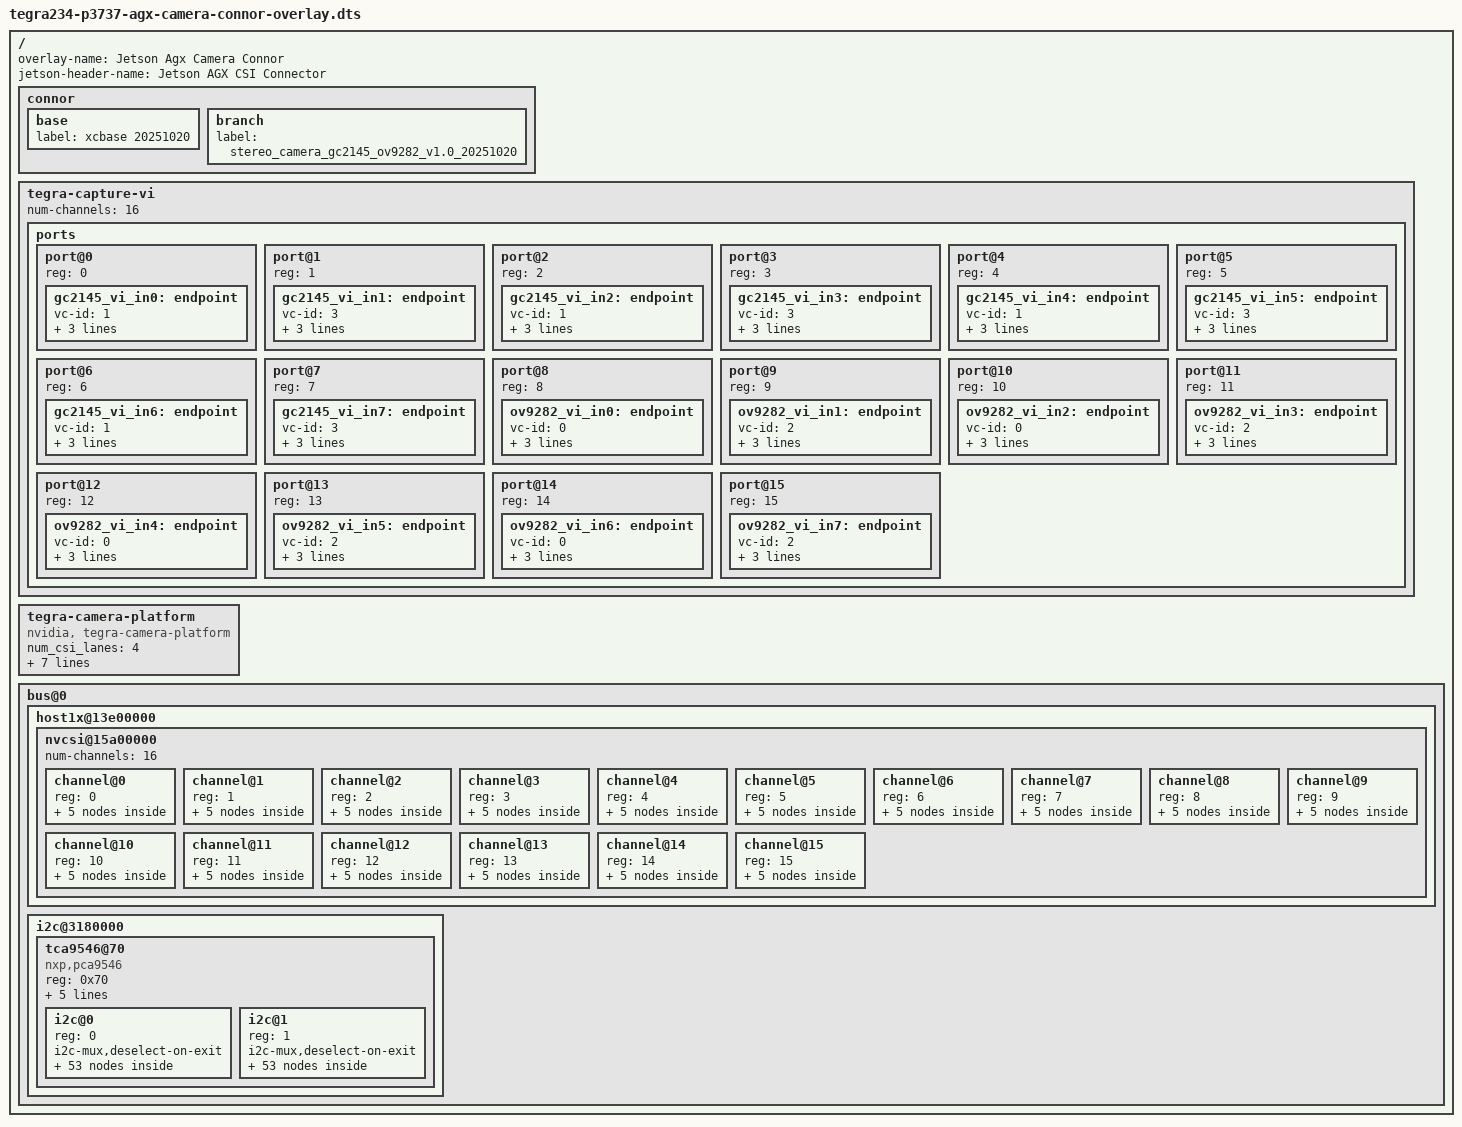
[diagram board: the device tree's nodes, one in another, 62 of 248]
// SPDX-License-Identifier: GPL-2.0-only
// SPDX-FileCopyrightText: Copyright (c) 2018-2023, NVIDIA CORPORATION & AFFILIATES. All rights reserved.

/dts-v1/;
/plugin/;

#include <dt-bindings/clock/tegra234-clock.h>
#include <dt-bindings/gpio/tegra234-gpio.h>
#include <dt-bindings/tegra234-p3737-0000+p3701-0000.h>

#define CAM0_RST_L	TEGRA234_MAIN_GPIO(H, 3)
#define CAM0_PWDN	TEGRA234_MAIN_GPIO(H, 6)
#define CAM1_RST_L	TEGRA234_MAIN_GPIO(AC, 1)
#define CAM1_PWDN	TEGRA234_MAIN_GPIO(AC, 0)
#define CAMERA_I2C_MUX_BUS(x) (0x1E + x)
#define XCFSYNC     TEGRA234_MAIN_GPIO(AC, 7)

/* camera control gpio definitions */
/ {
	overlay-name = "Jetson Agx Camera Connor";
	jetson-header-name = "Jetson AGX CSI Connector";
    compatible = JETSON_COMPATIBLE;

	fragment@0 {
		target-path = "/";

		__overlay__ {
			connor {
				base {
					label = "xcbase 20251020";
				};
				branch {
					label = "stereo_camera_gc2145_ov9282_v1.0_20251020";
				};
			};
			tegra-capture-vi {
				num-channels = <16>;
				ports {
					#address-cells = <1>;
					#size-cells = <0>;
					status = "okay";
					port@0 {
						status = "okay";
						reg = <0>;
						gc2145_vi_in0: endpoint {
							status = "okay";
							vc-id = <1>;
							port-index = <0>;
							bus-width = <4>;
							remote-endpoint = <&gc2145_csi_out0>;
						};
					};
					port@1 {
						status = "okay";
						reg = <1>;
						gc2145_vi_in1: endpoint {
							status = "okay";
							vc-id = <3>;
							port-index = <0>;
							bus-width = <4>;
							remote-endpoint = <&gc2145_csi_out1>;
						};
					};
					port@2 {
						status = "okay";
						reg = <2>;
						gc2145_vi_in2: endpoint {
							status = "okay";
							vc-id = <1>;
							port-index = <4>;
							bus-width = <4>;
							remote-endpoint = <&gc2145_csi_out2>;
						};
					};
					port@3 {
						status = "okay";
						reg = <3>;
						gc2145_vi_in3: endpoint {
							status = "okay";
							vc-id = <3>;
							port-index = <4>;
							bus-width = <4>;
							remote-endpoint = <&gc2145_csi_out3>;
						};
					};
					port@4 {
						status = "okay";
						reg = <4>;
						gc2145_vi_in4: endpoint {
							status = "okay";
							vc-id = <1>;
							port-index = <2>;
							bus-width = <4>;
							remote-endpoint = <&gc2145_csi_out4>;
						};
					};
					port@5 {
						status = "okay";
						reg = <5>;
						gc2145_vi_in5: endpoint {
							status = "okay";
							vc-id = <3>;
							port-index = <2>;
							bus-width = <4>;
							remote-endpoint = <&gc2145_csi_out5>;
						};
					};
					port@6 {
						status = "okay";
						reg = <6>;
						gc2145_vi_in6: endpoint {
							status = "okay";
							vc-id = <1>;
							port-index = <5>;
							bus-width = <4>;
							remote-endpoint = <&gc2145_csi_out6>;
						};
					};
					port@7 {
						status = "okay";
						reg = <7>;
						gc2145_vi_in7: endpoint {
							status = "okay";
							vc-id = <3>;
							port-index = <5>;
							bus-width = <4>;
							remote-endpoint = <&gc2145_csi_out7>;
						};
					};
					port@8 {
						status = "okay";
						reg = <8>;
						ov9282_vi_in0: endpoint {
							status = "okay";
							vc-id = <0>;
							port-index = <0>;
							bus-width = <4>;
							remote-endpoint = <&ov9282_csi_out0>;
						};
					};
					port@9 {
						status = "okay";
						reg = <9>;
						ov9282_vi_in1: endpoint {
							status = "okay";
							vc-id = <2>;
							port-index = <0>;
							bus-width = <4>;
							remote-endpoint = <&ov9282_csi_out1>;
						};
					};
					port@10 {
						status = "okay";
						reg = <10>;
						ov9282_vi_in2: endpoint {
							status = "okay";
							vc-id = <0>;
							port-index = <4>;
							bus-width = <4>;
							remote-endpoint = <&ov9282_csi_out2>;
						};
					};
					port@11 {
						status = "okay";
						reg = <11>;
						ov9282_vi_in3: endpoint {
							status = "okay";
							vc-id = <2>;
							port-index = <4>;
							bus-width = <4>;
							remote-endpoint = <&ov9282_csi_out3>;
						};
					};
					port@12 {
						status = "okay";
						reg = <12>;
						ov9282_vi_in4: endpoint {
							status = "okay";
							vc-id = <0>;
							port-index = <2>;
							bus-width = <4>;
							remote-endpoint = <&ov9282_csi_out4>;
						};
					};
					port@13 {
						status = "okay";
						reg = <13>;
						ov9282_vi_in5: endpoint {
							status = "okay";
							vc-id = <2>;
							port-index = <2>;
							bus-width = <4>;
							remote-endpoint = <&ov9282_csi_out5>;
						};
					};
					port@14 {
						status = "okay";
						reg = <14>;
						ov9282_vi_in6: endpoint {
							status = "okay";
							vc-id = <0>;
							port-index = <5>;
							bus-width = <4>;
							remote-endpoint = <&ov9282_csi_out6>;
						};
					};
					port@15 {
						status = "okay";
						reg = <15>;
						ov9282_vi_in7: endpoint {
							status = "okay";
							vc-id = <2>;
							port-index = <5>;
							bus-width = <4>;
							remote-endpoint = <&ov9282_csi_out7>;
						};						
					};
				};
			};
            
			tegra-camera-platform {
				compatible = "nvidia, tegra-camera-platform";
				num_csi_lanes = <4>;
				max_lane_speed = <2500000000>;
				min_bits_per_pixel = <10>;
				vi_peak_byte_per_pixel = <2>;
				vi_bw_margin_pct = <25>;
				max_pixel_rate = <165000000>;
				isp_peak_byte_per_pixel = <5>;
				isp_bw_margin_pct = <25>;
			};

			bus@0{
				host1x@13e00000 {
					nvcsi@15a00000 {
						num-channels = <16>;
						channel@0 {
							status = "okay";
							reg = <0>;
							ports {
								status = "okay";
								#address-cells = <1>;
								#size-cells = <0>;
								port@0 {
									status = "okay";
									reg = <0>;
									gc2145_csi_in0: endpoint {
										status = "okay";
										port-index = <0>;
										bus-width = <4>;
										remote-endpoint = <&gc2145_cam_out0>;
									};
								};
								port@1 {
									status = "okay";
									reg = <1>;
									gc2145_csi_out0: endpoint {
										status = "okay";
										remote-endpoint = <&gc2145_vi_in0>;
									};
								};
							};
						};
						channel@1 {
							status = "okay";
							reg = <1>;
							ports {
								status = "okay";
								#address-cells = <1>;
								#size-cells = <0>;
								port@0 {
									status = "okay";
									reg = <0>;
									gc2145_csi_in1: endpoint {
										status = "okay";
										port-index = <0>;
										bus-width = <4>;
										remote-endpoint = <&gc2145_cam_out1>;
									};
								};
								port@1 {
									status = "okay";
									reg = <1>;
									gc2145_csi_out1: endpoint {
										status = "okay";
										remote-endpoint = <&gc2145_vi_in1>;
									};
								};
							};
						};
						channel@2 {
							status = "okay";
							reg = <2>;
							ports {
								status = "okay";
								#address-cells = <1>;
								#size-cells = <0>;
								port@0 {
									status = "okay";
									reg = <0>;
									gc2145_csi_in2: endpoint {
										status = "okay";
										port-index = <4>;
										bus-width = <4>;
										remote-endpoint = <&gc2145_cam_out2>;
									};
								};
								port@1 {
									status = "okay";
									reg = <1>;
									gc2145_csi_out2: endpoint {
										status = "okay";
										remote-endpoint = <&gc2145_vi_in2>;
									};
								};
							};
						};
						channel@3 {
							status = "okay";
							reg = <3>;
							ports {
								status = "okay";
								#address-cells = <1>;
								#size-cells = <0>;
								port@0 {
									status = "okay";
									reg = <0>;
									gc2145_csi_in3: endpoint {
										status = "okay";
										port-index = <4>;
										bus-width = <4>;
										remote-endpoint = <&gc2145_cam_out3>;
									};
								};
								port@1 {
									status = "okay";
									reg = <1>;
									gc2145_csi_out3: endpoint {
										status = "okay";
										remote-endpoint = <&gc2145_vi_in3>;
									};
								};
							};
						};
						channel@4 {
							status = "okay";
							reg = <4>;
							ports {
								status = "okay";
								#address-cells = <1>;
								#size-cells = <0>;
								port@0 {
									status = "okay";
									reg = <0>;
									gc2145_csi_in4: endpoint {
										status = "okay";
										port-index = <2>;
										bus-width = <4>;
										remote-endpoint = <&gc2145_cam_out4>;
									};
								};
								port@1 {
									status = "okay";
									reg = <1>;
									gc2145_csi_out4: endpoint {
										status = "okay";
										remote-endpoint = <&gc2145_vi_in4>;
									};
								};
							};
						};
						channel@5 {
							status = "okay";
							reg = <5>;
							ports {
								status = "okay";
								#address-cells = <1>;
								#size-cells = <0>;
								port@0 {
									status = "okay";
									reg = <0>;
									gc2145_csi_in5: endpoint {
										status = "okay";
										port-index = <2>;
										bus-width = <4>;
										remote-endpoint = <&gc2145_cam_out5>;
									};
								};
								port@1 {
									status = "okay";
									reg = <1>;
									gc2145_csi_out5: endpoint {
										status = "okay";
										remote-endpoint = <&gc2145_vi_in5>;
									};
								};
							};
						};
						channel@6 {
							status = "okay";
							reg = <6>;
							ports {
								status = "okay";
								#address-cells = <1>;
								#size-cells = <0>;
								port@0 {
									status = "okay";
									reg = <0>;
									gc2145_csi_in6: endpoint {
										status = "okay";
										port-index = <6>;
										bus-width = <4>;
										remote-endpoint = <&gc2145_cam_out6>;
									};
								};
								port@1 {
									status = "okay";
									reg = <1>;
									gc2145_csi_out6: endpoint {
										status = "okay";
										remote-endpoint = <&gc2145_vi_in6>;
									};
								};
							};
						};
						channel@7 {
							status = "okay";
							reg = <7>;
							ports {
								status = "okay";
								#address-cells = <1>;
								#size-cells = <0>;
								port@0 {
									status = "okay";
									reg = <0>;
									gc2145_csi_in7: endpoint {
										status = "okay";
										port-index = <6>;
										bus-width = <4>;
										remote-endpoint = <&gc2145_cam_out7>;
									};
								};
								port@1 {
									status = "okay";
									reg = <1>;
									gc2145_csi_out7: endpoint {
										status = "okay";
										remote-endpoint = <&gc2145_vi_in7>;
									};
								};
							};
						};
						channel@8 {
							status = "okay";
							reg = <8>;
							ports {
								status = "okay";
								#address-cells = <1>;
								#size-cells = <0>;
								port@0 {
									status = "okay";
									reg = <0>;
									ov9282_csi_in0: endpoint {
										status = "okay";
										port-index = <0>;
										bus-width = <4>;
										remote-endpoint = <&ov9282_cam_out0>;
									};
								};
								port@1 {
									status = "okay";
									reg = <1>;
									ov9282_csi_out0: endpoint {
										status = "okay";
										remote-endpoint = <&ov9282_vi_in0>;
									};
								};
							};
						};
						channel@9 {
							status = "okay";
							reg = <9>;
							ports {
								status = "okay";
								#address-cells = <1>;
								#size-cells = <0>;
								port@0 {
									status = "okay";
									reg = <0>;
									ov9282_csi_in1: endpoint {
										status = "okay";
										port-index = <0>;
										bus-width = <4>;
										remote-endpoint = <&ov9282_cam_out1>;
									};
								};
								port@1 {
									status = "okay";
									reg = <1>;
									ov9282_csi_out1: endpoint {
										status = "okay";
										remote-endpoint = <&ov9282_vi_in1>;
									};
								};
							};
						};
						channel@10 {
							status = "okay";
							reg = <10>;
							ports {
								status = "okay";
								#address-cells = <1>;
								#size-cells = <0>;
								port@0 {
									status = "okay";
									reg = <0>;
									ov9282_csi_in2: endpoint {
										status = "okay";
										port-index = <4>;
										bus-width = <4>;
										remote-endpoint = <&ov9282_cam_out2>;
									};
								};
								port@1 {
									status = "okay";
									reg = <1>;
									ov9282_csi_out2: endpoint {
										status = "okay";
										remote-endpoint = <&ov9282_vi_in2>;
									};
								};
							};
						};
						channel@11 {
							status = "okay";
							reg = <11>;
							ports {
								status = "okay";
								#address-cells = <1>;
								#size-cells = <0>;
								port@0 {
									status = "okay";
									reg = <0>;
									ov9282_csi_in3: endpoint {
										status = "okay";
										port-index = <4>;
										bus-width = <4>;
										remote-endpoint = <&ov9282_cam_out3>;
									};
								};
								port@1 {
									status = "okay";
									reg = <1>;
									ov9282_csi_out3: endpoint {
										status = "okay";
										remote-endpoint = <&ov9282_vi_in3>;
									};
								};
							};
						};
						channel@12 {
							status = "okay";
							reg = <12>;
							ports {
								status = "okay";
								#address-cells = <1>;
								#size-cells = <0>;
								port@0 {
									status = "okay";
									reg = <0>;
									ov9282_csi_in4: endpoint {
										status = "okay";
										port-index = <2>;
										bus-width = <4>;
										remote-endpoint = <&ov9282_cam_out4>;
									};
								};
								port@1 {
									status = "okay";
									reg = <1>;
									ov9282_csi_out4: endpoint {
										status = "okay";
										remote-endpoint = <&ov9282_vi_in4>;
									};
								};
							};
						};
						channel@13 {
							status = "okay";
							reg = <13>;
							ports {
								status = "okay";
								#address-cells = <1>;
								#size-cells = <0>;
								port@0 {
									status = "okay";
									reg = <0>;
									ov9282_csi_in5: endpoint {
										status = "okay";
										port-index = <2>;
										bus-width = <4>;
										remote-endpoint = <&ov9282_cam_out5>;
									};
								};
								port@1 {
									status = "okay";
									reg = <1>;
									ov9282_csi_out5: endpoint {
										status = "okay";
										remote-endpoint = <&ov9282_vi_in5>;
									};
								};
							};
						};
						channel@14 {
							status = "okay";
							reg = <14>;
							ports {
								status = "okay";
								#address-cells = <1>;
								#size-cells = <0>;
								port@0 {
									status = "okay";
									reg = <0>;
									ov9282_csi_in6: endpoint {
										status = "okay";
										port-index = <6>;
										bus-width = <4>;
										remote-endpoint = <&ov9282_cam_out6>;
									};
								};
								port@1 {
									status = "okay";
									reg = <1>;
									ov9282_csi_out6: endpoint {
										status = "okay";
										remote-endpoint = <&ov9282_vi_in6>;
									};
								};
							};
						};
						channel@15 {
							status = "okay";
							reg = <15>;
							ports {
								status = "okay";
								#address-cells = <1>;
								#size-cells = <0>;
								port@0 {
									status = "okay";
									reg = <0>;
									ov9282_csi_in7: endpoint {
										status = "okay";
										port-index = <6>;
										bus-width = <4>;
										remote-endpoint = <&ov9282_cam_out7>;
									};
								};
								port@1 {
									status = "okay";
									reg = <1>;
									ov9282_csi_out7: endpoint {
										status = "okay";
										remote-endpoint = <&ov9282_vi_in7>;
									};
								};
							};
						};
					};
				};

                i2c@3180000 {
					tca9546@70 {
						status = "okay";
						compatible = "nxp,pca9546";
						reg = <0x70>;
						#address-cells = <1>;
						#size-cells = <0>;
						skip_mux_detect = "yes";
						force_bus_start = <CAMERA_I2C_MUX_BUS(0)>;
						vif-supply = <&vdd_1v8_sys>;
						vcc-supply = <&vdd_1v8_sys>;
						vcc_lp = "vcc";
						i2c@0 {
							reg = <0>;
							i2c-mux,deselect-on-exit;
							#address-cells = <1>;
							#size-cells = <0>;
							status = "okay";
							dser_0: max96712 {
								status = "okay";
								compatible = "Connor,abh_max96712";
                    			reg = <0x29>;
								is-master;
                			};
							gc2145_a {
								status = "okay";
								def-addr = <0x3c>; /* actual i2c address of sensor */
								nvidia,gmsl-dser-device = <&dser_0>;
								des-link = "A";

								compatible = "Connor,abh_max9295d";

								reg = <0x10>; /* 9295 will translate to this i2c address */

								physical_w = "15.0";
								physical_h = "12.5";
								sensor_model ="gc2145";
								post_crop_frame_drop = "0";
								use_decibel_gain = "true";

								/* enable CID_SENSOR_MODE_ID for sensor modes selection */
								use_sensor_mode_id = "true";

								mode0 {
									mclk_khz = "24000";
									num_lanes = "2";
									tegra_sinterface = "serial_a";
									vc_id = "0";
									discontinuous_clk = "yes";
									dpcm_enable = "false";
									cil_settletime = "0";
									dynamic_pixel_bit_depth = "16";
									csi_pixel_bit_depth = "16"; 
									mode_type = "yuv";
									pixel_phase = "uyvy";

									active_w = "1600";
									active_h = "1200";
									readout_orientation = "0";
									line_length = "2800";
									inherent_gain = "1";
									pix_clk_hz = "165000000";
									serdes_pix_clk_hz = "2400000000";

									gain_factor = "10";
									min_gain_val = "0"; /* dB */
									max_gain_val = "420"; /* dB */
									step_gain_val = "3"; /* 0.3 */
									default_gain = "150";
									min_hdr_ratio = "1";
									max_hdr_ratio = "1";
									framerate_factor = "1000000";
									min_framerate = "30000000";
									max_framerate = "30000000";
									step_framerate = "1";
									default_framerate = "30000000";
									exposure_factor = "1000000";
									min_exp_time = "59"; /*us, 2 lines*/
									max_exp_time = "33333";
									step_exp_time = "1";
									default_exp_time = "33333";/* us */
									embedded_metadata_height = "0";
								};

								mode1 {
									mclk_khz = "24000";
									num_lanes = "2";
									tegra_sinterface = "serial_a";
									vc_id = "0";
									discontinuous_clk = "yes";
									dpcm_enable = "false";
									cil_settletime = "0";
									dynamic_pixel_bit_depth = "16";
									csi_pixel_bit_depth = "16"; 
									mode_type = "yuv";
									pixel_phase = "uyvy";

									active_w = "1280";
									active_h = "720";
									readout_orientation = "0";
									line_length = "2800";
									inherent_gain = "1";
									pix_clk_hz = "165000000";
									serdes_pix_clk_hz = "2400000000";

									gain_factor = "10";
									min_gain_val = "0"; /* dB */
									max_gain_val = "420"; /* dB */
									step_gain_val = "3"; /* 0.3 */
									default_gain = "150";
									min_hdr_ratio = "1";
									max_hdr_ratio = "1";
									framerate_factor = "1000000";
									min_framerate = "30000000";
									max_framerate = "30000000";
									step_framerate = "1";
									default_framerate = "30000000";
									exposure_factor = "1000000";
									min_exp_time = "59"; /*us, 2 lines*/
									max_exp_time = "33333";
									step_exp_time = "1";
									default_exp_time = "33333";/* us */
									embedded_metadata_height = "0";
								};

								ports {
									#address-cells = <1>;
									#size-cells = <0>;
									port@0 {
										reg = <0>;
										gc2145_cam_out0: endpoint {
											vc-id = <1>;
											port-index = <0>;
											bus-width = <4>;
											remote-endpoint = <&gc2145_csi_in0>;
										};
									};
								};
								gmsl-link {
									num-ser-lanes = <2>;
									streams = "yuv16";
								};
							};
							gc2145_b {
								status = "okay";
								def-addr = <0x3c>; /* actual i2c address of sensor */
								nvidia,gmsl-dser-device = <&dser_0>;
								des-link = "B";

								compatible = "Connor,abh_max9295d";

								reg = <0x11>; /* 9295 will translate to this i2c address */

								physical_w = "15.0";
								physical_h = "12.5";
								sensor_model ="gc2145";
								post_crop_frame_drop = "0";
								use_decibel_gain = "true";

								/* enable CID_SENSOR_MODE_ID for sensor modes selection */
								use_sensor_mode_id = "true";
								
								mode0 {
									mclk_khz = "24000";
									num_lanes = "2";
									tegra_sinterface = "serial_a";
									vc_id = "2";
									discontinuous_clk = "no";
									dpcm_enable = "false";
									cil_settletime = "0";
									dynamic_pixel_bit_depth = "16";
									csi_pixel_bit_depth = "16"; 
									mode_type = "yuv";
									pixel_phase = "uyvy";

									active_w = "1600";
									active_h = "1200";
									readout_orientation = "0";
									line_length = "2800";
									inherent_gain = "1";
									pix_clk_hz = "165000000";
									serdes_pix_clk_hz = "2400000000";

									gain_factor = "10";
									min_gain_val = "0"; /* dB */
									max_gain_val = "420"; /* dB */
									step_gain_val = "3"; /* 0.3 */
									default_gain = "150";
									min_hdr_ratio = "1";
									max_hdr_ratio = "1";
									framerate_factor = "1000000";
									min_framerate = "30000000";
									max_framerate = "30000000";
									step_framerate = "1";
									default_framerate = "30000000";
									exposure_factor = "1000000";
									min_exp_time = "59"; /*us, 2 lines*/
									max_exp_time = "33333";
									step_exp_time = "1";
									default_exp_time = "33333";/* us */
									embedded_metadata_height = "0";
								};
								mode1 {
									mclk_khz = "24000";
									num_lanes = "2";
									tegra_sinterface = "serial_a";
									vc_id = "2";
									discontinuous_clk = "yes";
									dpcm_enable = "false";
									cil_settletime = "0";
									dynamic_pixel_bit_depth = "16";
									csi_pixel_bit_depth = "16"; 
									mode_type = "yuv";
									pixel_phase = "uyvy";

									active_w = "1280";
									active_h = "720";
									readout_orientation = "0";
									line_length = "2800";
									inherent_gain = "1";
									pix_clk_hz = "165000000";
									serdes_pix_clk_hz = "2400000000";

									gain_factor = "10";
									min_gain_val = "0"; /* dB */
									max_gain_val = "420"; /* dB */
									step_gain_val = "3"; /* 0.3 */
									default_gain = "150";
									min_hdr_ratio = "1";
									max_hdr_ratio = "1";
									framerate_factor = "1000000";
									min_framerate = "30000000";
									max_framerate = "30000000";
									step_framerate = "1";
									default_framerate = "30000000";
									exposure_factor = "1000000";
									min_exp_time = "59"; /*us, 2 lines*/
									max_exp_time = "33333";
									step_exp_time = "1";
									default_exp_time = "33333";/* us */
									embedded_metadata_height = "0";
								};

								ports {
									#address-cells = <1>;
									#size-cells = <0>;
									port@0 {
										reg = <0>;
										gc2145_cam_out1: endpoint {
											vc-id = <3>;
											port-index = <0>;
											bus-width = <4>;
											remote-endpoint = <&gc2145_csi_in1>;
										};
									};
								};
								gmsl-link {
									num-ser-lanes = <2>;
									streams = "yuv16";
								};
							};
							gc2145_c {
								status = "okay";
								def-addr = <0x3c>; /* actual i2c address of sensor */
								nvidia,gmsl-dser-device = <&dser_0>;
								des-link = "C";

								compatible = "Connor,abh_max9295d";

								reg = <0x12>; /* 9295 will translate to this i2c address */

								physical_w = "15.0";
								physical_h = "12.5";
								sensor_model ="gc2145";
								post_crop_frame_drop = "0";
								use_decibel_gain = "true";

								/* enable CID_SENSOR_MODE_ID for sensor modes selection */
								use_sensor_mode_id = "true";

								mode0 {
									
									mclk_khz = "24000";
									num_lanes = "2";
									tegra_sinterface = "serial_a";
									vc_id = "2";
									discontinuous_clk = "yes";
									dpcm_enable = "false";
									cil_settletime = "0";
									dynamic_pixel_bit_depth = "16";
									csi_pixel_bit_depth = "16"; 
									mode_type = "yuv";
									pixel_phase = "uyvy";

									active_w = "1600";
									active_h = "1200";
									readout_orientation = "0";
									line_length = "2800";
									inherent_gain = "1";
									pix_clk_hz = "165000000";
									serdes_pix_clk_hz = "2400000000";

									gain_factor = "10";
									min_gain_val = "0"; /* dB */
									max_gain_val = "420"; /* dB */
									step_gain_val = "3"; /* 0.3 */
									default_gain = "150";
									min_hdr_ratio = "1";
									max_hdr_ratio = "1";
									framerate_factor = "1000000";
									min_framerate = "30000000";
									max_framerate = "30000000";
									step_framerate = "1";
									default_framerate = "30000000";
									exposure_factor = "1000000";
									min_exp_time = "59"; /*us, 2 lines*/
									max_exp_time = "33333";
									step_exp_time = "1";
									default_exp_time = "33333";/* us */
									embedded_metadata_height = "0";
								};

								mode1 {
									mclk_khz = "24000";
									num_lanes = "2";
									tegra_sinterface = "serial_a";
									vc_id = "2";
									discontinuous_clk = "yes";
									dpcm_enable = "false";
									cil_settletime = "0";
									dynamic_pixel_bit_depth = "16";
									csi_pixel_bit_depth = "16"; 
									mode_type = "yuv";
									pixel_phase = "uyvy";

									active_w = "1280";
									active_h = "720";
									readout_orientation = "0";
									line_length = "2800";
									inherent_gain = "1";
									pix_clk_hz = "165000000";
									serdes_pix_clk_hz = "2400000000";

									gain_factor = "10";
									min_gain_val = "0"; /* dB */
									max_gain_val = "420"; /* dB */
									step_gain_val = "3"; /* 0.3 */
									default_gain = "150";
									min_hdr_ratio = "1";
									max_hdr_ratio = "1";
									framerate_factor = "1000000";
									min_framerate = "30000000";
									max_framerate = "30000000";
									step_framerate = "1";
									default_framerate = "30000000";
									exposure_factor = "1000000";
									min_exp_time = "59"; /*us, 2 lines*/
									max_exp_time = "33333";
									step_exp_time = "1";
									default_exp_time = "33333";/* us */
									embedded_metadata_height = "0";
								};
								ports {
									#address-cells = <1>;
									#size-cells = <0>;
									port@0 {
										reg = <0>;
										gc2145_cam_out2: endpoint {
											vc-id = <1>;
											port-index = <4>;
											bus-width = <4>;
											remote-endpoint = <&gc2145_csi_in2>;
										};
									};
								};
								gmsl-link {
									num-ser-lanes = <2>;
									streams = "yuv16";
								};
							};
							gc2145_d {
								status = "okay";
								def-addr = <0x3c>; /* actual i2c address of sensor */
								nvidia,gmsl-dser-device = <&dser_0>;
								des-link = "D";

								compatible = "Connor,abh_max9295d";

								reg = <0x13>; /* 9295 will translate to this i2c address */

								physical_w = "15.0";
								physical_h = "12.5";
								sensor_model ="gc2145";
								post_crop_frame_drop = "0";
								use_decibel_gain = "true";

								/* enable CID_SENSOR_MODE_ID for sensor modes selection */
								use_sensor_mode_id = "true";

								mode0 {
									
									mclk_khz = "24000";
									num_lanes = "2";
									tegra_sinterface = "serial_a";
									vc_id = "2";
									discontinuous_clk = "no";
									dpcm_enable = "false";
									cil_settletime = "0";
									dynamic_pixel_bit_depth = "16";
									csi_pixel_bit_depth = "16"; 
									mode_type = "yuv";
									pixel_phase = "uyvy";

									active_w = "1600";
									active_h = "1200";
									readout_orientation = "0";
									line_length = "2800";
									inherent_gain = "1";
									pix_clk_hz = "165000000";
									serdes_pix_clk_hz = "2400000000";

									gain_factor = "10";
									min_gain_val = "0"; /* dB */
									max_gain_val = "420"; /* dB */
									step_gain_val = "3"; /* 0.3 */
									default_gain = "150";
									min_hdr_ratio = "1";
									max_hdr_ratio = "1";
									framerate_factor = "1000000";
									min_framerate = "30000000";
									max_framerate = "30000000";
									step_framerate = "1";
									default_framerate = "30000000";
									exposure_factor = "1000000";
									min_exp_time = "59"; /*us, 2 lines*/
									max_exp_time = "33333";
									step_exp_time = "1";
									default_exp_time = "33333";/* us */
									embedded_metadata_height = "0";
								};
								mode1 {
									mclk_khz = "24000";
									num_lanes = "2";
									tegra_sinterface = "serial_a";
									vc_id = "2";
									discontinuous_clk = "yes";
									dpcm_enable = "false";
									cil_settletime = "0";
									dynamic_pixel_bit_depth = "16";
									csi_pixel_bit_depth = "16"; 
									mode_type = "yuv";
									pixel_phase = "uyvy";

									active_w = "1280";
									active_h = "720";
									readout_orientation = "0";
									line_length = "2800";
									inherent_gain = "1";
									pix_clk_hz = "165000000";
									serdes_pix_clk_hz = "2400000000";

									gain_factor = "10";
									min_gain_val = "0"; /* dB */
									max_gain_val = "420"; /* dB */
									step_gain_val = "3"; /* 0.3 */
									default_gain = "150";
									min_hdr_ratio = "1";
									max_hdr_ratio = "1";
									framerate_factor = "1000000";
									min_framerate = "30000000";
									max_framerate = "30000000";
									step_framerate = "1";
									default_framerate = "30000000";
									exposure_factor = "1000000";
									min_exp_time = "59"; /*us, 2 lines*/
									max_exp_time = "33333";
									step_exp_time = "1";
									default_exp_time = "33333";/* us */
									embedded_metadata_height = "0";
								};

								ports {
									#address-cells = <1>;
									#size-cells = <0>;
									port@0 {
										reg = <0>;
										gc2145_cam_out3: endpoint {
											vc-id = <3>;
											port-index = <4>;
											bus-width = <4>;
											remote-endpoint = <&gc2145_csi_in3>;
										};
									};
								};
								gmsl-link {
									num-ser-lanes = <2>;
									streams = "yuv16";
								};
							};

							ov9282_a {
								status = "okay";
								def-addr = <0x37>; /* actual i2c address of sensor */
								nvidia,gmsl-dser-device = <&dser_0>;
								des-link = "A";

								compatible = "Connor,abh_deepth_max9295d";

								reg = <0x14>; /* 9295 will translate to this i2c address */

								physical_w = "15.0";
								physical_h = "12.5";
								sensor_model ="ov9282";
								post_crop_frame_drop = "0";
								use_decibel_gain = "true";

								/* enable CID_SENSOR_MODE_ID for sensor modes selection */
								use_sensor_mode_id = "true";

								mode0 {
									mclk_khz = "24000";
									num_lanes = "2";
									tegra_sinterface = "serial_a";
									vc_id = "1";
									discontinuous_clk = "no";
									dpcm_enable = "false";
									cil_settletime = "0";
									dynamic_pixel_bit_depth = "8";
									csi_pixel_bit_depth = "8"; 
									mode_type = "bayer";
									pixel_phase = "bggr";
									pixel_t = "bayer_bggr8";

									active_w = "1280";
									active_h = "400";
									readout_orientation = "0";
									line_length = "2200";
									inherent_gain = "1";
									pix_clk_hz = "165000000";
									serdes_pix_clk_hz = "2400000000";

									gain_factor = "10";
									min_gain_val = "0"; /* dB */
									max_gain_val = "420"; /* dB */
									step_gain_val = "3"; /* 0.3 */
									default_gain = "150";
									min_hdr_ratio = "1";
									max_hdr_ratio = "1";
									framerate_factor = "1000000";
									min_framerate = "30000000";
									max_framerate = "30000000";
									step_framerate = "1";
									default_framerate = "30000000";
									exposure_factor = "1000000";
									min_exp_time = "59"; /*us, 2 lines*/
									max_exp_time = "33333";
									step_exp_time = "1";
									default_exp_time = "33333";/* us */
									embedded_metadata_height = "0";
								};
								ports {
									#address-cells = <1>;
									#size-cells = <0>;
									port@0 {
										reg = <0>;
										ov9282_cam_out0: endpoint {
											vc-id = <0>;
											port-index = <0>;
											bus-width = <4>;
											remote-endpoint = <&ov9282_csi_in0>;
										};
									};
								};
								gmsl-link {
									num-ser-lanes = <2>;
									streams = "raw8";
								};
							};
							ov9282_b {
								status = "okay";
								def-addr = <0x37>; /* actual i2c address of sensor */
								nvidia,gmsl-dser-device = <&dser_0>;
								des-link = "B";

								compatible = "Connor,abh_deepth_max9295d";

								reg = <0x15>; /* 9295 will translate to this i2c address */

								physical_w = "15.0";
								physical_h = "12.5";
								sensor_model ="ov9282";
								post_crop_frame_drop = "0";
								use_decibel_gain = "true";

								/* enable CID_SENSOR_MODE_ID for sensor modes selection */
								use_sensor_mode_id = "true";

								mode0 {
									mclk_khz = "24000";
									num_lanes = "2";
									tegra_sinterface = "serial_a";
									vc_id = "3";
									discontinuous_clk = "no";
									dpcm_enable = "false";
									cil_settletime = "0";
									dynamic_pixel_bit_depth = "8";
									csi_pixel_bit_depth = "8"; 
									mode_type = "bayer";
									pixel_phase = "bggr";
									pixel_t = "bayer_bggr8";

									active_w = "1280";
									active_h = "400";
									readout_orientation = "0";
									line_length = "2200";
									inherent_gain = "1";
									pix_clk_hz = "165000000";
									serdes_pix_clk_hz = "2400000000";

									gain_factor = "10";
									min_gain_val = "0"; /* dB */
									max_gain_val = "420"; /* dB */
									step_gain_val = "3"; /* 0.3 */
									default_gain = "150";
									min_hdr_ratio = "1";
									max_hdr_ratio = "1";
									framerate_factor = "1000000";
									min_framerate = "30000000";
									max_framerate = "30000000";
									step_framerate = "1";
									default_framerate = "30000000";
									exposure_factor = "1000000";
									min_exp_time = "59"; /*us, 2 lines*/
									max_exp_time = "33333";
									step_exp_time = "1";
									default_exp_time = "33333";/* us */
									embedded_metadata_height = "0";
								};
								ports {
									#address-cells = <1>;
									#size-cells = <0>;
									port@0 {
										reg = <0>;
										ov9282_cam_out1: endpoint {
											vc-id = <2>;
											port-index = <0>;
											bus-width = <4>;
											remote-endpoint = <&ov9282_csi_in1>;
										};
									};
								};
								gmsl-link {
									num-ser-lanes = <2>;
									streams = "raw8";
								};
							};
							ov9282_c {
								status = "okay";
								def-addr = <0x37>; /* actual i2c address of sensor */
								nvidia,gmsl-dser-device = <&dser_0>;
								des-link = "C";

								compatible = "Connor,abh_deepth_max9295d";

								reg = <0x16>; /* 9295 will translate to this i2c address */

								physical_w = "15.0";
								physical_h = "12.5";
								sensor_model ="ov9282";
								post_crop_frame_drop = "0";
								use_decibel_gain = "true";

								/* enable CID_SENSOR_MODE_ID for sensor modes selection */
								use_sensor_mode_id = "true";

								mode0 {
									
									mclk_khz = "24000";
									num_lanes = "2";
									tegra_sinterface = "serial_a";
									vc_id = "1";
									discontinuous_clk = "no";
									dpcm_enable = "false";
									cil_settletime = "0";
									dynamic_pixel_bit_depth = "8";
									csi_pixel_bit_depth = "8"; 
									mode_type = "bayer";
									pixel_phase = "bggr";
									pixel_t = "bayer_bggr8";

									active_w = "1280";
									active_h = "400";
									readout_orientation = "0";
									line_length = "2200";
									inherent_gain = "1";
									pix_clk_hz = "165000000";
									serdes_pix_clk_hz = "2400000000";

									gain_factor = "10";
									min_gain_val = "0"; /* dB */
									max_gain_val = "420"; /* dB */
									step_gain_val = "3"; /* 0.3 */
									default_gain = "150";
									min_hdr_ratio = "1";
									max_hdr_ratio = "1";
									framerate_factor = "1000000";
									min_framerate = "30000000";
									max_framerate = "30000000";
									step_framerate = "1";
									default_framerate = "30000000";
									exposure_factor = "1000000";
									min_exp_time = "59"; /*us, 2 lines*/
									max_exp_time = "33333";
									step_exp_time = "1";
									default_exp_time = "33333";/* us */
									embedded_metadata_height = "0";
								};
								ports {
									#address-cells = <1>;
									#size-cells = <0>;
									port@0 {
										reg = <0>;
										ov9282_cam_out2: endpoint {
											vc-id = <0>;
											port-index = <4>;
											bus-width = <4>;
											remote-endpoint = <&ov9282_csi_in2>;
										};
									};
								};
								gmsl-link {
									num-ser-lanes = <2>;
									streams = "raw8";
								};
							};
							ov9282_d {
								status = "okay";
								def-addr = <0x37>; /* actual i2c address of sensor */
								nvidia,gmsl-dser-device = <&dser_0>;
								des-link = "D";

								compatible = "Connor,abh_deepth_max9295d";

								reg = <0x17>; /* 9295 will translate to this i2c address */

								physical_w = "15.0";
								physical_h = "12.5";
								sensor_model ="ov9282";
								post_crop_frame_drop = "0";
								use_decibel_gain = "true";

								/* enable CID_SENSOR_MODE_ID for sensor modes selection */
								use_sensor_mode_id = "true";

								mode0 {
									
									mclk_khz = "24000";
									num_lanes = "2";
									tegra_sinterface = "serial_a";
									vc_id = "3";
									discontinuous_clk = "no";
									dpcm_enable = "false";
									cil_settletime = "0";
									dynamic_pixel_bit_depth = "8";
									csi_pixel_bit_depth = "8"; 
									mode_type = "bayer";
									pixel_t = "bayer_bggr8";
									pixel_phase = "bggr";

									active_w = "1280";
									active_h = "400";
									readout_orientation = "0";
									line_length = "2200";
									inherent_gain = "1";
									pix_clk_hz = "165000000";
									serdes_pix_clk_hz = "2400000000";

									gain_factor = "10";
									min_gain_val = "0"; /* dB */
									max_gain_val = "420"; /* dB */
									step_gain_val = "3"; /* 0.3 */
									default_gain = "150";
									min_hdr_ratio = "1";
									max_hdr_ratio = "1";
									framerate_factor = "1000000";
									min_framerate = "30000000";
									max_framerate = "30000000";
									step_framerate = "1";
									default_framerate = "30000000";
									exposure_factor = "1000000";
									min_exp_time = "59"; /*us, 2 lines*/
									max_exp_time = "33333";
									step_exp_time = "1";
									default_exp_time = "33333";/* us */
									embedded_metadata_height = "0";
								};

								ports {
									#address-cells = <1>;
									#size-cells = <0>;
									port@0 {
										reg = <0>;
										ov9282_cam_out3: endpoint {
											vc-id = <2>;
											port-index = <4>;
											bus-width = <4>;
											remote-endpoint = <&ov9282_csi_in3>;
										};
									};
								};
								gmsl-link {
									num-ser-lanes = <2>;
									streams = "raw8";
								};
							};
						};
						i2c@1 {
							reg = <1>;
							i2c-mux,deselect-on-exit;
							#address-cells = <1>;
							#size-cells = <0>;
							status = "okay";
							dser_1: max96712 {
								status = "okay";
								compatible = "Connor,abh_max96712";
                    			reg = <0x29>;
                			};
							gc2145_a {
								status = "okay";
								def-addr = <0x3c>; /* actual i2c address of sensor */
								nvidia,gmsl-dser-device = <&dser_1>;
								des-link = "A";

								compatible = "Connor,abh_max9295d";

								reg = <0x10>; /* 9295 will translate to this i2c address */

								physical_w = "15.0";
								physical_h = "12.5";
								sensor_model ="gc2145";
								post_crop_frame_drop = "0";
								use_decibel_gain = "true";

								/* enable CID_SENSOR_MODE_ID for sensor modes selection */
								use_sensor_mode_id = "true";

								mode0 {
									mclk_khz = "24000";
									num_lanes = "2";
									tegra_sinterface = "serial_a";
									vc_id = "0";
									discontinuous_clk = "yes";
									dpcm_enable = "false";
									cil_settletime = "0";
									dynamic_pixel_bit_depth = "16";
									csi_pixel_bit_depth = "16"; 
									mode_type = "yuv";
									pixel_phase = "uyvy";

									active_w = "1600";
									active_h = "1200";
									readout_orientation = "0";
									line_length = "2800";
									inherent_gain = "1";
									pix_clk_hz = "165000000";
									serdes_pix_clk_hz = "2400000000";

									gain_factor = "10";
									min_gain_val = "0"; /* dB */
									max_gain_val = "420"; /* dB */
									step_gain_val = "3"; /* 0.3 */
									default_gain = "150";
									min_hdr_ratio = "1";
									max_hdr_ratio = "1";
									framerate_factor = "1000000";
									min_framerate = "30000000";
									max_framerate = "30000000";
									step_framerate = "1";
									default_framerate = "30000000";
									exposure_factor = "1000000";
									min_exp_time = "59"; /*us, 2 lines*/
									max_exp_time = "33333";
									step_exp_time = "1";
									default_exp_time = "33333";/* us */
									embedded_metadata_height = "0";
								};

								mode1 {
									mclk_khz = "24000";
									num_lanes = "2";
									tegra_sinterface = "serial_a";
									vc_id = "0";
									discontinuous_clk = "yes";
									dpcm_enable = "false";
									cil_settletime = "0";
									dynamic_pixel_bit_depth = "16";
									csi_pixel_bit_depth = "16"; 
									mode_type = "yuv";
									pixel_phase = "uyvy";

									active_w = "1280";
									active_h = "720";
									readout_orientation = "0";
									line_length = "2800";
									inherent_gain = "1";
									pix_clk_hz = "165000000";
									serdes_pix_clk_hz = "2400000000";

									gain_factor = "10";
									min_gain_val = "0"; /* dB */
									max_gain_val = "420"; /* dB */
									step_gain_val = "3"; /* 0.3 */
									default_gain = "150";
									min_hdr_ratio = "1";
									max_hdr_ratio = "1";
									framerate_factor = "1000000";
									min_framerate = "30000000";
									max_framerate = "30000000";
									step_framerate = "1";
									default_framerate = "30000000";
									exposure_factor = "1000000";
									min_exp_time = "59"; /*us, 2 lines*/
									max_exp_time = "33333";
									step_exp_time = "1";
									default_exp_time = "33333";/* us */
									embedded_metadata_height = "0";
								};

								ports {
									#address-cells = <1>;
									#size-cells = <0>;
									port@0 {
										reg = <0>;
										gc2145_cam_out4: endpoint {
											vc-id = <1>;
											port-index = <2>;
											bus-width = <4>;
											remote-endpoint = <&gc2145_csi_in4>;
										};
									};
								};
								gmsl-link {
									num-ser-lanes = <2>;
									streams = "yuv16";
								};
							};
							gc2145_b {
								status = "okay";
								def-addr = <0x3c>; /* actual i2c address of sensor */
								nvidia,gmsl-dser-device = <&dser_1>;
								des-link = "B";

								compatible = "Connor,abh_max9295d";

								reg = <0x11>; /* 9295 will translate to this i2c address */

								physical_w = "15.0";
								physical_h = "12.5";
								sensor_model ="gc2145";
								post_crop_frame_drop = "0";
								use_decibel_gain = "true";

								/* enable CID_SENSOR_MODE_ID for sensor modes selection */
								use_sensor_mode_id = "true";
								
								mode0 {
									mclk_khz = "24000";
									num_lanes = "2";
									tegra_sinterface = "serial_a";
									vc_id = "2";
									discontinuous_clk = "no";
									dpcm_enable = "false";
									cil_settletime = "0";
									dynamic_pixel_bit_depth = "16";
									csi_pixel_bit_depth = "16"; 
									mode_type = "yuv";
									pixel_phase = "uyvy";

									active_w = "1600";
									active_h = "1200";
									readout_orientation = "0";
									line_length = "2800";
									inherent_gain = "1";
									pix_clk_hz = "165000000";
									serdes_pix_clk_hz = "2400000000";

									gain_factor = "10";
									min_gain_val = "0"; /* dB */
									max_gain_val = "420"; /* dB */
									step_gain_val = "3"; /* 0.3 */
									default_gain = "150";
									min_hdr_ratio = "1";
									max_hdr_ratio = "1";
									framerate_factor = "1000000";
									min_framerate = "30000000";
									max_framerate = "30000000";
									step_framerate = "1";
									default_framerate = "30000000";
									exposure_factor = "1000000";
									min_exp_time = "59"; /*us, 2 lines*/
									max_exp_time = "33333";
									step_exp_time = "1";
									default_exp_time = "33333";/* us */
									embedded_metadata_height = "0";
								};
								mode1 {
									mclk_khz = "24000";
									num_lanes = "2";
									tegra_sinterface = "serial_a";
									vc_id = "2";
									discontinuous_clk = "yes";
									dpcm_enable = "false";
									cil_settletime = "0";
									dynamic_pixel_bit_depth = "16";
									csi_pixel_bit_depth = "16"; 
									mode_type = "yuv";
									pixel_phase = "uyvy";

									active_w = "1280";
									active_h = "720";
									readout_orientation = "0";
									line_length = "2800";
									inherent_gain = "1";
									pix_clk_hz = "165000000";
									serdes_pix_clk_hz = "2400000000";

									gain_factor = "10";
									min_gain_val = "0"; /* dB */
									max_gain_val = "420"; /* dB */
									step_gain_val = "3"; /* 0.3 */
									default_gain = "150";
									min_hdr_ratio = "1";
									max_hdr_ratio = "1";
									framerate_factor = "1000000";
									min_framerate = "30000000";
									max_framerate = "30000000";
									step_framerate = "1";
									default_framerate = "30000000";
									exposure_factor = "1000000";
									min_exp_time = "59"; /*us, 2 lines*/
									max_exp_time = "33333";
									step_exp_time = "1";
									default_exp_time = "33333";/* us */
									embedded_metadata_height = "0";
								};

								ports {
									#address-cells = <1>;
									#size-cells = <0>;
									port@0 {
										reg = <0>;
										gc2145_cam_out5: endpoint {
											vc-id = <3>;
											port-index = <2>;
											bus-width = <4>;
											remote-endpoint = <&gc2145_csi_in5>;
										};
									};
								};
								gmsl-link {
									num-ser-lanes = <2>;
									streams = "yuv16";
								};
							};
							gc2145_c {
								status = "okay";
								def-addr = <0x3c>; /* actual i2c address of sensor */
								nvidia,gmsl-dser-device = <&dser_1>;
								des-link = "C";

								compatible = "Connor,abh_max9295d";

								reg = <0x12>; /* 9295 will translate to this i2c address */

								physical_w = "15.0";
								physical_h = "12.5";
								sensor_model ="gc2145";
								post_crop_frame_drop = "0";
								use_decibel_gain = "true";

								/* enable CID_SENSOR_MODE_ID for sensor modes selection */
								use_sensor_mode_id = "true";

								mode0 {
									
									mclk_khz = "24000";
									num_lanes = "2";
									tegra_sinterface = "serial_a";
									vc_id = "2";
									discontinuous_clk = "yes";
									dpcm_enable = "false";
									cil_settletime = "0";
									dynamic_pixel_bit_depth = "16";
									csi_pixel_bit_depth = "16"; 
									mode_type = "yuv";
									pixel_phase = "uyvy";

									active_w = "1600";
									active_h = "1200";
									readout_orientation = "0";
									line_length = "2800";
									inherent_gain = "1";
									pix_clk_hz = "165000000";
									serdes_pix_clk_hz = "2400000000";

									gain_factor = "10";
									min_gain_val = "0"; /* dB */
									max_gain_val = "420"; /* dB */
									step_gain_val = "3"; /* 0.3 */
									default_gain = "150";
									min_hdr_ratio = "1";
									max_hdr_ratio = "1";
									framerate_factor = "1000000";
									min_framerate = "30000000";
									max_framerate = "30000000";
									step_framerate = "1";
									default_framerate = "30000000";
									exposure_factor = "1000000";
									min_exp_time = "59"; /*us, 2 lines*/
									max_exp_time = "33333";
									step_exp_time = "1";
									default_exp_time = "33333";/* us */
									embedded_metadata_height = "0";
								};

								mode1 {
									mclk_khz = "24000";
									num_lanes = "2";
									tegra_sinterface = "serial_a";
									vc_id = "2";
									discontinuous_clk = "yes";
									dpcm_enable = "false";
									cil_settletime = "0";
									dynamic_pixel_bit_depth = "16";
									csi_pixel_bit_depth = "16"; 
									mode_type = "yuv";
									pixel_phase = "uyvy";

									active_w = "1280";
									active_h = "720";
									readout_orientation = "0";
									line_length = "2800";
									inherent_gain = "1";
									pix_clk_hz = "165000000";
									serdes_pix_clk_hz = "2400000000";

									gain_factor = "10";
									min_gain_val = "0"; /* dB */
									max_gain_val = "420"; /* dB */
									step_gain_val = "3"; /* 0.3 */
									default_gain = "150";
									min_hdr_ratio = "1";
									max_hdr_ratio = "1";
									framerate_factor = "1000000";
									min_framerate = "30000000";
									max_framerate = "30000000";
									step_framerate = "1";
									default_framerate = "30000000";
									exposure_factor = "1000000";
									min_exp_time = "59"; /*us, 2 lines*/
									max_exp_time = "33333";
									step_exp_time = "1";
									default_exp_time = "33333";/* us */
									embedded_metadata_height = "0";
								};
								ports {
									#address-cells = <1>;
									#size-cells = <0>;
									port@0 {
										reg = <0>;
										gc2145_cam_out6: endpoint {
											vc-id = <1>;
											port-index = <6>;
											bus-width = <4>;
											remote-endpoint = <&gc2145_csi_in6>;
										};
									};
								};
								gmsl-link {
									num-ser-lanes = <2>;
									streams = "yuv16";
								};
							};
							gc2145_d {
								status = "okay";
								def-addr = <0x3c>; /* actual i2c address of sensor */
								nvidia,gmsl-dser-device = <&dser_1>;
								des-link = "D";

								compatible = "Connor,abh_max9295d";

								reg = <0x13>; /* 9295 will translate to this i2c address */

								physical_w = "15.0";
								physical_h = "12.5";
								sensor_model ="gc2145";
								post_crop_frame_drop = "0";
								use_decibel_gain = "true";

								/* enable CID_SENSOR_MODE_ID for sensor modes selection */
								use_sensor_mode_id = "true";

								mode0 {
									
									mclk_khz = "24000";
									num_lanes = "2";
									tegra_sinterface = "serial_a";
									vc_id = "2";
									discontinuous_clk = "no";
									dpcm_enable = "false";
									cil_settletime = "0";
									dynamic_pixel_bit_depth = "16";
									csi_pixel_bit_depth = "16"; 
									mode_type = "yuv";
									pixel_phase = "uyvy";

									active_w = "1600";
									active_h = "1200";
									readout_orientation = "0";
									line_length = "2800";
									inherent_gain = "1";
									pix_clk_hz = "165000000";
									serdes_pix_clk_hz = "2400000000";

									gain_factor = "10";
									min_gain_val = "0"; /* dB */
									max_gain_val = "420"; /* dB */
									step_gain_val = "3"; /* 0.3 */
									default_gain = "150";
									min_hdr_ratio = "1";
									max_hdr_ratio = "1";
									framerate_factor = "1000000";
									min_framerate = "30000000";
									max_framerate = "30000000";
									step_framerate = "1";
									default_framerate = "30000000";
									exposure_factor = "1000000";
									min_exp_time = "59"; /*us, 2 lines*/
									max_exp_time = "33333";
									step_exp_time = "1";
									default_exp_time = "33333";/* us */
									embedded_metadata_height = "0";
								};

								mode1 {
									mclk_khz = "24000";
									num_lanes = "2";
									tegra_sinterface = "serial_a";
									vc_id = "2";
									discontinuous_clk = "yes";
									dpcm_enable = "false";
									cil_settletime = "0";
									dynamic_pixel_bit_depth = "16";
									csi_pixel_bit_depth = "16"; 
									mode_type = "yuv";
									pixel_phase = "uyvy";

									active_w = "1280";
									active_h = "720";
									readout_orientation = "0";
									line_length = "2800";
									inherent_gain = "1";
									pix_clk_hz = "165000000";
									serdes_pix_clk_hz = "2400000000";

									gain_factor = "10";
									min_gain_val = "0"; /* dB */
									max_gain_val = "420"; /* dB */
									step_gain_val = "3"; /* 0.3 */
									default_gain = "150";
									min_hdr_ratio = "1";
									max_hdr_ratio = "1";
									framerate_factor = "1000000";
									min_framerate = "30000000";
									max_framerate = "30000000";
									step_framerate = "1";
									default_framerate = "30000000";
									exposure_factor = "1000000";
									min_exp_time = "59"; /*us, 2 lines*/
									max_exp_time = "33333";
									step_exp_time = "1";
									default_exp_time = "33333";/* us */
									embedded_metadata_height = "0";
								};
								ports {
									#address-cells = <1>;
									#size-cells = <0>;
									port@0 {
										reg = <0>;
										gc2145_cam_out7: endpoint {
											vc-id = <3>;
											port-index = <6>;
											bus-width = <4>;
											remote-endpoint = <&gc2145_csi_in7>;
										};
									};
								};
								gmsl-link {
									num-ser-lanes = <2>;
									streams = "yuv16";
								};
							};

							ov9282_a {
								status = "okay";
								def-addr = <0x37>; /* actual i2c address of sensor */
								nvidia,gmsl-dser-device = <&dser_1>;
								des-link = "A";

								compatible = "Connor,abh_deepth_max9295d";

								reg = <0x14>; /* 9295 will translate to this i2c address */

								physical_w = "15.0";
								physical_h = "12.5";
								sensor_model ="ov9282";
								post_crop_frame_drop = "0";
								use_decibel_gain = "true";

								/* enable CID_SENSOR_MODE_ID for sensor modes selection */
								use_sensor_mode_id = "true";

								mode0 {
									mclk_khz = "24000";
									num_lanes = "2";
									tegra_sinterface = "serial_a";
									vc_id = "0";
									discontinuous_clk = "no";
									dpcm_enable = "false";
									cil_settletime = "0";
									dynamic_pixel_bit_depth = "8";
									csi_pixel_bit_depth = "8"; 
									mode_type = "bayer";
									pixel_phase = "bggr";
									pixel_t = "bayer_bggr8";

									active_w = "1280";
									active_h = "400";
									readout_orientation = "0";
									line_length = "2200";
									inherent_gain = "1";
									pix_clk_hz = "165000000";
									serdes_pix_clk_hz = "2400000000";

									gain_factor = "10";
									min_gain_val = "0"; /* dB */
									max_gain_val = "420"; /* dB */
									step_gain_val = "3"; /* 0.3 */
									default_gain = "150";
									min_hdr_ratio = "1";
									max_hdr_ratio = "1";
									framerate_factor = "1000000";
									min_framerate = "30000000";
									max_framerate = "30000000";
									step_framerate = "1";
									default_framerate = "30000000";
									exposure_factor = "1000000";
									min_exp_time = "59"; /*us, 2 lines*/
									max_exp_time = "33333";
									step_exp_time = "1";
									default_exp_time = "33333";/* us */
									embedded_metadata_height = "0";
								};
								ports {
									#address-cells = <1>;
									#size-cells = <0>;
									port@0 {
										reg = <0>;
										ov9282_cam_out4: endpoint {
											vc-id = <0>;
											port-index = <2>;
											bus-width = <4>;
											remote-endpoint = <&ov9282_csi_in4>;
										};
									};
								};
								gmsl-link {
									num-ser-lanes = <2>;
									streams = "raw8";
								};
							};
							ov9282_b {
								status = "okay";
								def-addr = <0x37>; /* actual i2c address of sensor */
								nvidia,gmsl-dser-device = <&dser_1>;
								des-link = "B";

								compatible = "Connor,abh_deepth_max9295d";

								reg = <0x15>; /* 9295 will translate to this i2c address */

								physical_w = "15.0";
								physical_h = "12.5";
								sensor_model ="ov9282";
								post_crop_frame_drop = "0";
								use_decibel_gain = "true";

								/* enable CID_SENSOR_MODE_ID for sensor modes selection */
								use_sensor_mode_id = "true";

								mode0 {
									mclk_khz = "24000";
									num_lanes = "2";
									tegra_sinterface = "serial_a";
									vc_id = "1";
									discontinuous_clk = "no";
									dpcm_enable = "false";
									cil_settletime = "0";
									dynamic_pixel_bit_depth = "8";
									csi_pixel_bit_depth = "8"; 
									mode_type = "bayer";
									pixel_phase = "bggr";
									pixel_t = "bayer_bggr8";

									active_w = "1280";
									active_h = "400";
									readout_orientation = "0";
									line_length = "2200";
									inherent_gain = "1";
									pix_clk_hz = "165000000";
									serdes_pix_clk_hz = "2400000000";

									gain_factor = "10";
									min_gain_val = "0"; /* dB */
									max_gain_val = "420"; /* dB */
									step_gain_val = "3"; /* 0.3 */
									default_gain = "150";
									min_hdr_ratio = "1";
									max_hdr_ratio = "1";
									framerate_factor = "1000000";
									min_framerate = "30000000";
									max_framerate = "30000000";
									step_framerate = "1";
									default_framerate = "30000000";
									exposure_factor = "1000000";
									min_exp_time = "59"; /*us, 2 lines*/
									max_exp_time = "33333";
									step_exp_time = "1";
									default_exp_time = "33333";/* us */
									embedded_metadata_height = "0";
								};
								ports {
									#address-cells = <1>;
									#size-cells = <0>;
									port@0 {
										reg = <0>;
										ov9282_cam_out5: endpoint {
											vc-id = <2>;
											port-index = <2>;
											bus-width = <4>;
											remote-endpoint = <&ov9282_csi_in5>;
										};
									};
								};
								gmsl-link {
									num-ser-lanes = <2>;
									streams = "raw8";
								};
							};
							ov9282_c {
								status = "okay";
								def-addr = <0x37>; /* actual i2c address of sensor */
								nvidia,gmsl-dser-device = <&dser_1>;
								des-link = "C";

								compatible = "Connor,abh_deepth_max9295d";

								reg = <0x16>; /* 9295 will translate to this i2c address */

								physical_w = "15.0";
								physical_h = "12.5";
								sensor_model ="ov9282";
								post_crop_frame_drop = "0";
								use_decibel_gain = "true";

								/* enable CID_SENSOR_MODE_ID for sensor modes selection */
								use_sensor_mode_id = "true";

								mode0 {
									mclk_khz = "24000";
									num_lanes = "2";
									tegra_sinterface = "serial_a";
									vc_id = "0";
									discontinuous_clk = "no";
									dpcm_enable = "false";
									cil_settletime = "0";
									dynamic_pixel_bit_depth = "8";
									csi_pixel_bit_depth = "8"; 
									mode_type = "bayer";
									pixel_phase = "bggr";
									pixel_t = "bayer_bggr8";

									active_w = "1280";
									active_h = "400";
									readout_orientation = "0";
									line_length = "2200";
									inherent_gain = "1";
									pix_clk_hz = "165000000";
									serdes_pix_clk_hz = "2400000000";

									gain_factor = "10";
									min_gain_val = "0"; /* dB */
									max_gain_val = "420"; /* dB */
									step_gain_val = "3"; /* 0.3 */
									default_gain = "150";
									min_hdr_ratio = "1";
									max_hdr_ratio = "1";
									framerate_factor = "1000000";
									min_framerate = "30000000";
									max_framerate = "30000000";
									step_framerate = "1";
									default_framerate = "30000000";
									exposure_factor = "1000000";
									min_exp_time = "59"; /*us, 2 lines*/
									max_exp_time = "33333";
									step_exp_time = "1";
									default_exp_time = "33333";/* us */
									embedded_metadata_height = "0";
								};
								ports {
									#address-cells = <1>;
									#size-cells = <0>;
									port@0 {
										reg = <0>;
										ov9282_cam_out6: endpoint {
											vc-id = <0>;
											port-index = <6>;
											bus-width = <4>;
											remote-endpoint = <&ov9282_csi_in6>;
										};
									};
								};
								gmsl-link {
									num-ser-lanes = <2>;
									streams = "raw8";
								};
							};
							ov9282_d {
								status = "okay";
								def-addr = <0x37>; /* actual i2c address of sensor */
								nvidia,gmsl-dser-device = <&dser_1>;
								des-link = "D";

								compatible = "Connor,abh_deepth_max9295d";

								reg = <0x17>; /* 9295 will translate to this i2c address */

								physical_w = "15.0";
								physical_h = "12.5";
								sensor_model ="ov9282";
								post_crop_frame_drop = "0";
								use_decibel_gain = "true";

								/* enable CID_SENSOR_MODE_ID for sensor modes selection */
								use_sensor_mode_id = "true";

								mode0 {
									mclk_khz = "24000";
									num_lanes = "2";
									tegra_sinterface = "serial_a";
									vc_id = "1";
									discontinuous_clk = "no";
									dpcm_enable = "false";
									cil_settletime = "0";
									dynamic_pixel_bit_depth = "8";
									csi_pixel_bit_depth = "8"; 
									mode_type = "bayer";
									pixel_t = "bayer_bggr8";
									pixel_phase = "bggr";

									active_w = "1280";
									active_h = "400";
									readout_orientation = "0";
									line_length = "2200";
									inherent_gain = "1";
									pix_clk_hz = "165000000";
									serdes_pix_clk_hz = "2400000000";

									gain_factor = "10";
									min_gain_val = "0"; /* dB */
									max_gain_val = "420"; /* dB */
									step_gain_val = "3"; /* 0.3 */
									default_gain = "150";
									min_hdr_ratio = "1";
									max_hdr_ratio = "1";
									framerate_factor = "1000000";
									min_framerate = "30000000";
									max_framerate = "30000000";
									step_framerate = "1";
									default_framerate = "30000000";
									exposure_factor = "1000000";
									min_exp_time = "59"; /*us, 2 lines*/
									max_exp_time = "33333";
									step_exp_time = "1";
									default_exp_time = "33333";/* us */
									embedded_metadata_height = "0";
								};

								ports {
									#address-cells = <1>;
									#size-cells = <0>;
									port@0 {
										reg = <0>;
										ov9282_cam_out7: endpoint {
											vc-id = <2>;
											port-index = <6>;
											bus-width = <4>;
											remote-endpoint = <&ov9282_csi_in7>;
										};
									};
								};
								gmsl-link {
									num-ser-lanes = <2>;
									streams = "raw8";
								};
							};
						};
					};
				};
			};
		};
	};
};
